# EQEP2_REG register map
Vendor: Texas Instruments
Peripheral module from a debugger description file (folder J722S).
Registers are 16-bit, read-write, reset 0x0 unless marked. A register's access mark holds for its fields unless they carry their own. Offsets are as the file gives them; lines under a group give offsets from that group; [hi:lo] are bit positions; {n}, {i} and the like mark numbered series; 'fields as' and 'values as' point back to an identical list; <NAME> marks a mode.

## EQEP2_REG
0x00 REG_QPOSCNT 32-bit — Position Counter
  [31:0] QPOSCNT — Position Counter This 32-bit position counter register counts up/down on every eQEP pulse based on direction input. This counter acts as a position integrator whose count value is proportional to position from a give reference point. This Register acts as a Read ONLY register while counter is counting up/down.
0x04 REG_QPOSINIT 32-bit — Position Counter Init
  [31:0] QPOSINIT — Position Counter InitThis register contains the position value that is used to initialize the position counter based on external strobe or index event. The position counter can be initialized through software. Writes to this register should always be full 32-bit writes.
0x08 REG_QPOSMAX 32-bit — Maximum Position Count
  [31:0] QPOSMAX — Maximum Position CountThis register contains the maximum position counter value. Writes to this register should always be full 32-bit writes.
0x0C REG_QPOSCMP 32-bit — Position Compare
  [31:0] QPOSCMP — Position Compare The position-compare value in this register is compared with the position counter [QPOSCNT] to generate sync output and/or interrupt on compare match.
0x10 REG_QPOSILAT 32-bit ro — Index Position Latch
  [31:0] QPOSILAT — Index Position Latch The position-counter value is latched into this register on an index event as defined by the QEPCTL[IEL] bits.
0x14 REG_QPOSSLAT 32-bit ro — Strobe Position Latch
  [31:0] QPOSSLAT — Strobe Position Latch The position-counter value is latched into this register on a strobe event as defined by the QEPCTL[SEL] bits.
0x18 REG_QPOSLAT 32-bit ro — Position Latch
  [31:0] QPOSLAT — Position Latch The position-counter value is latched into this register on a unit time out event.
0x1C REG_QUTMR 32-bit — QEP Unit Timer
  [31:0] QUTMR — QEP Unit TimerThis register acts as time base for unit time event generation. When this timer value matches the unit time period value a unit time event is generated.
0x20 REG_QUPRD 32-bit — QEP Unit Period
  [31:0] QUPRD — QEP Unit PeriodThis register contains the period count for the unit timer to generate periodic unit time events. These events latch the eQEP position information at periodic intervals and optionally generate an interrupt. Writes to this register should always be full 32-bit writes.
0x24 REG_QWDTMR — QEP Watchdog Timer
  [15:0] QWDTMR — QEP Watchdog Timer This register acts as time base for the watchdog to detect motor stalls. When this timer value matches with the watchdog's period value a watchdog timeout interrupt is generated. This register is reset upon edge transition in quadrature-clock indicating the motion.
0x26 REG_QWDPRD — QEP Watchdog Period
  [15:0] QWDPRD — QEP Watchdog Period This register contains the time-out count for the eQEP peripheral watch dog timer.When the watchdog timer value matches the watchdog period value, a watchdog timeout interrupt is generated.
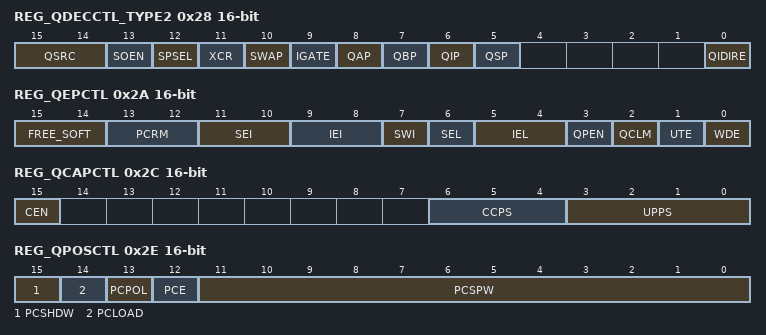
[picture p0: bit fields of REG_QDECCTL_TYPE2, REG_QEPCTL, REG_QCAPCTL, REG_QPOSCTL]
0x28 REG_QDECCTL_TYPE2 — Quadrature Decoder Control
  [15:14] QSRC — Position-counter source selection
  [13] SOEN — Sync output-enable
  [12] SPSEL — Sync output pin selection
  [11] XCR — External Clock Rate
  [10] SWAP — CLK/DIR Signal Source for Position Counter
  [9] IGATE — Index pulse gating option
  [8] QAP — QEPA input polarity
  [7] QBP — QEPB input polarity
  [6] QIP — QEPI input polarity
  [5] QSP — QEPS input polarity
  [0] QIDIRE — 0 - Compatible mode, Behavior same as existing devices1 - Enhancement for Direction change during Index will be enabled
0x2A REG_QEPCTL — QEP Control
  [15:14] FREE_SOFT — Emulation mode
  [13:12] PCRM — Postion counter reset
  [11:10] SEI — Strobe event initialization of position counter
  [9:8] IEI — Index event init of position count
  [7] SWI — Software init position counter
  [6] SEL — Strobe event latch of position counter
  [5:4] IEL — Index event latch of position counter [software index marker]
  [3] QPEN — Quadrature position counter enable/software reset
  [2] QCLM — QEP capture latch mode
  [1] UTE — QEP unit timer enable
  [0] WDE — QEP watchdog enable
0x2C REG_QCAPCTL — Qaudrature Capture Control
  [15] CEN — Enable eQEP capture
  [6:4] CCPS — eQEP capture timer clock prescaler
  [3:0] UPPS — Unit position event prescaler
0x2E REG_QPOSCTL — Position Compare Control
  [15] PCSHDW — Position compare of shadow enable
  [14] PCLOAD — Position compare of shadow load
  [13] PCPOL — Polarity of sync output
  [12] PCE — Position compare enable/disable
  [11:0] PCSPW — Select-position-compare sync output pulse width
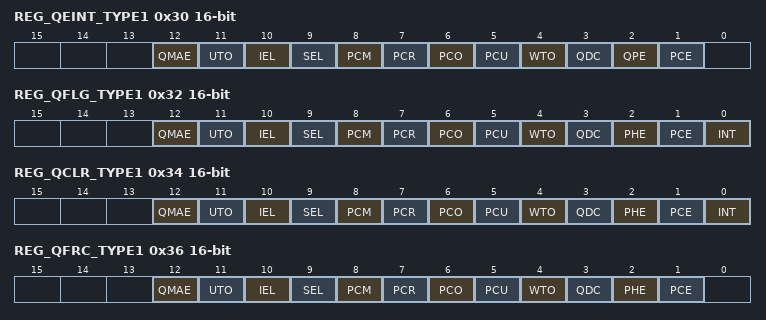
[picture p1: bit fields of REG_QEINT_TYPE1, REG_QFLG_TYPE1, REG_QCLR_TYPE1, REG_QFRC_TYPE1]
0x30 REG_QEINT_TYPE1 — QEP Interrupt Control
  [12] QMAE — QMA Error Interrupt enable
  [11] UTO — Unit time out interrupt enable
  [10] IEL — Index event latch interrupt enable
  [9] SEL — Strobe event latch interrupt enable
  [8] PCM — Position-compare match interrupt enable
  [7] PCR — Position-compare ready interrupt enable
  [6] PCO — Position counter overflow interrupt enable
  [5] PCU — Position counter underflow interrupt enable
  [4] WTO — Watchdog time out interrupt enable
  [3] QDC — Quadrature direction change interrupt enable
  [2] QPE — Quadrature phase error interrupt enable
  [1] PCE — Position counter error interrupt enable
0x32 REG_QFLG_TYPE1 ro — QEP Interrupt Flag
  [12] QMAE — QMA Error interrupt flag
  [11] UTO — Unit time out interrupt flag
  [10] IEL — Index event latch interrupt flag
  [9] SEL — Strobe event latch interrupt flag
  [8] PCM — eQEP compare match event interrupt flag
  [7] PCR — Position-compare ready interrupt flag
  [6] PCO — Position counter overflow interrupt flag
  [5] PCU — Position counter underflow interrupt flag
  [4] WTO — Watchdog timeout interrupt flag
  [3] QDC — Quadrature direction change interrupt flag
  [2] PHE — Quadrature phase error interrupt flag
  [1] PCE — Position counter error interrupt flag
  [0] INT — Global interrupt status flag
0x34 REG_QCLR_TYPE1 — QEP Interrupt Clear
  [12] QMAE — Clear QMA Error interrupt flag
  [11] UTO — Clear unit time out interrupt flag
  [10] IEL — Clear index event latch interrupt flag
  [9] SEL — Clear strobe event latch interrupt flag
  [8] PCM — Clear eQEP compare match event interrupt flag
  [7] PCR — Clear position-compare ready interrupt flag
  [6] PCO — Clear position counter overflow interrupt flag
  [5] PCU — Clear position counter underflow interrupt flag
  [4] WTO — Clear watchdog timeout interrupt flag
  [3] QDC — Clear quadrature direction change interrupt flag
  [2] PHE — Clear quadrature phase error interrupt flag
  [1] PCE — Clear position counter error interrupt flag
  [0] INT — Global interrupt clear flag
0x36 REG_QFRC_TYPE1 — QEP Interrupt Force
  [12] QMAE — Force QMA error interrupt
  [11] UTO — Force unit time out interrupt
  [10] IEL — Force index event latch interrupt
  [9] SEL — Force strobe event latch interrupt
  [8] PCM — Force position-compare match interrupt
  [7] PCR — Force position-compare ready interrupt
  [6] PCO — Force position counter overflow interrupt
  [5] PCU — Force position counter underflow interrupt
  [4] WTO — Force watchdog time out interrupt
  [3] QDC — Force quadrature direction change interrupt
  [2] PHE — Force quadrature phase error interrupt
  [1] PCE — Force position counter error interrupt
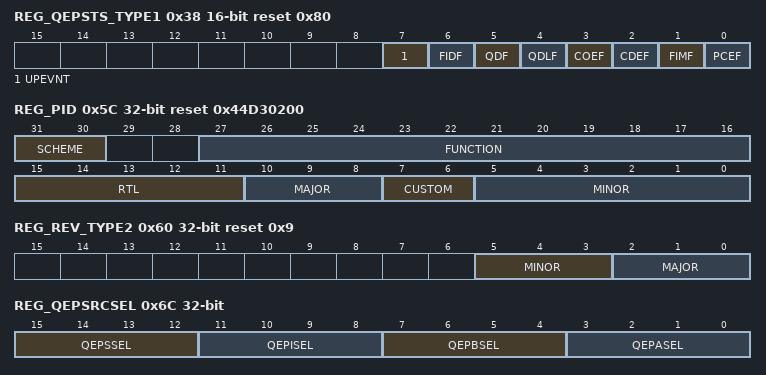
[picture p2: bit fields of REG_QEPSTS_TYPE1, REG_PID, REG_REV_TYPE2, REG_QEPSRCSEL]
0x38 REG_QEPSTS_TYPE1 access per field reset 0x80 — QEP Status
  [7] UPEVNT rw — Unit position event flag
  [6] FIDF ro — Direction on the first index markerStatus of the direction is latched on the first index event marker.
  [5] QDF ro — Quadrature direction flag
  [4] QDLF ro — eQEP direction latch flag
  [3] COEF rw — Capture overflow error flag
  [2] CDEF rw — Capture direction error flag
  [1] FIMF rw — First index marker flag
  [0] PCEF ro — Position counter error flag. This bit is not sticky and it is updated for every index event.
0x3A REG_QCTMR — QEP Capture Timer
  [15:0] QCTMR — This register provides time base for edge capture unit.
0x3C REG_QCPRD — QEP Capture Period
  [15:0] QCPRD — This register holds the period count value between the last successive eQEP position events
0x3E REG_QCTMRLAT ro — QEP Capture Latch
  [15:0] QCTMRLAT — The eQEP capture timer value can be latched into this register on two events viz., unit timeout event, reading the eQEP position counter.
0x40 REG_QCPRDLAT ro — QEP Capture Period Latch
  [15:0] QCPRDLAT — eQEP capture period value can be latched into this register on two events viz., unit timeout event, reading the eQEP position counter.
0x42 REG_Reserved_1 access not given reset not defined
0x5C REG_PID 32-bit ro reset 0x44D30200
  [31:30] SCHEME, [27:16] FUNCTION, [15:11] RTL, [10:8] MAJOR, [7:6] CUSTOM, [5:0] MINOR
0x60 REG_REV_TYPE2 32-bit ro reset 0x9 — QEP Revision Number
  [5:3] MINOR — This field specifies the Minor Revision number for the eQEP IP.
  [2:0] MAJOR — This field specifies the Major Revision number for the eQEP IP.
0x64 REG_QEPSTROBESEL 32-bit — QEP Strobe select register
  [1:0] STROBESEL — Strobe source select:
0x68 REG_QMACTRL 32-bit — QMA Control register
  [2:0] MODE — Select Mode for QMA mode:000 : QMA Module is bypassed. 001 : QMA Mode-1 operation selected010 : QMA Mode-2 operation selected011 : QMA Module is bypassed [reserved]1xx : QMA Module is bypassed [reserved]
0x6C REG_QEPSRCSEL 32-bit — QEP Source Select Register
  [15:12] QEPSSEL — QEP Strobe source select:0000: From device Pins [Default].0001-1111: Device dependent.
  [11:8] QEPISEL — QEP Index source select:0000: From device Pins [Default].0001-1111: Device dependent.
  [7:4] QEPBSEL — QEPB source select:0000: From device Pins [Default].0001-1111: Device dependent.
  [3:0] QEPASEL — QEPA source select:0000: From device Pins [Default].0001-1111: Device dependent.
0x70 REG_Reserved_2 access not given reset not defined
